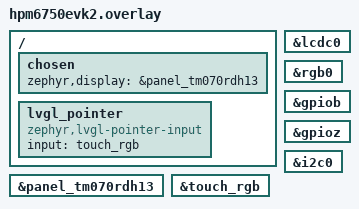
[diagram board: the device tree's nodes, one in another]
/*
 * Copyright 2024 HPMicro
 * SPDX-License-Identifier: Apache-2.0
 */

/ {
    chosen {
        zephyr,display = &panel_tm070rdh13;
    };

    lvgl_pointer {
		compatible = "zephyr,lvgl-pointer-input";
		input = <&touch_rgb>;
	};
};

&lcdc0 {
    status = "okay";
};

&rgb0 {
    status = "okay";
};

&panel_tm070rdh13 {
    status = "okay";
};

/*
 * backlight control
 */
&gpiob {
    status = "okay";
};

&gpioz {
    status = "okay";
};

&i2c0 {
    status = "okay";
};

&touch_rgb {
    status = "okay";
};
